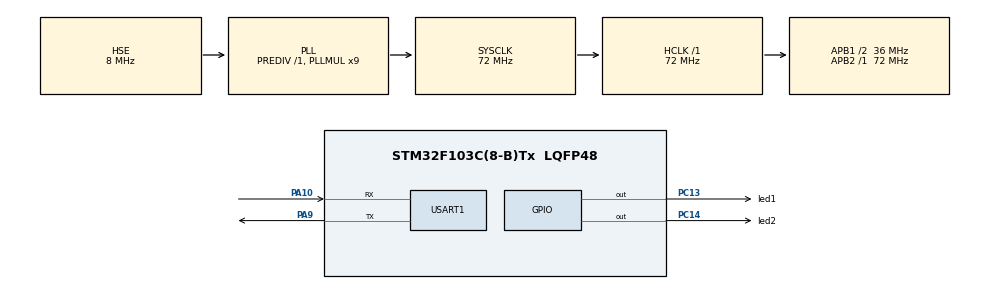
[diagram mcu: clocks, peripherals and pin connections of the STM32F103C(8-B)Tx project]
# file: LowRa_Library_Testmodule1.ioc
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Dma.Request0=USART1_RX
Dma.Request1=USART1_TX
Dma.USART1_RX.0.Direction=DMA_PERIPH_TO_MEMORY
Dma.USART1_RX.0.Instance=DMA1_Channel5
Dma.USART1_RX.0.MemDataAlignment=DMA_MDATAALIGN_BYTE
Dma.USART1_RX.0.MemInc=DMA_MINC_ENABLE
Dma.USART1_RX.0.Mode=DMA_NORMAL
Dma.USART1_RX.0.PeriphDataAlignment=DMA_PDATAALIGN_BYTE
Dma.USART1_RX.0.PeriphInc=DMA_PINC_DISABLE
Dma.USART1_RX.0.Priority=DMA_PRIORITY_LOW
Dma.USART1_TX.1.Direction=DMA_MEMORY_TO_PERIPH
Dma.USART1_TX.1.Instance=DMA1_Channel4
Dma.USART1_TX.1.MemDataAlignment=DMA_MDATAALIGN_BYTE
Dma.USART1_TX.1.MemInc=DMA_MINC_ENABLE
Dma.USART1_TX.1.Mode=DMA_NORMAL
Dma.USART1_TX.1.PeriphDataAlignment=DMA_PDATAALIGN_BYTE
Dma.USART1_TX.1.PeriphInc=DMA_PINC_DISABLE
Dma.USART1_TX.1.Priority=DMA_PRIORITY_LOW
Mcu.Family=STM32F1
Mcu.Name=STM32F103C(8-B)Tx
Mcu.Package=LQFP48
NVIC.DMA1_Channel4_IRQn=true\:0\:0\:false\:false\:true\:false\:true
NVIC.DMA1_Channel5_IRQn=true\:0\:0\:false\:false\:true\:false\:true
NVIC.PriorityGroup=NVIC_PRIORITYGROUP_4
NVIC.USART1_IRQn=true\:0\:0\:false\:false\:true\:true\:true
PA10.Mode=Asynchronous
PA10.Signal=USART1_RX
PA13.Mode=Serial_Wire
PA13.Signal=SYS_JTMS-SWDIO
PA14.Mode=Serial_Wire
PA14.Signal=SYS_JTCK-SWCLK
PA9.Mode=Asynchronous
PA9.Signal=USART1_TX
PC13-TAMPER-RTC.GPIO_Label=led1
PC13-TAMPER-RTC.Signal=GPIO_Output
PC14-OSC32_IN.GPIO_Label=led2
PC14-OSC32_IN.Signal=GPIO_Output
PD0-OSC_IN.Mode=HSE-External-Oscillator
PD0-OSC_IN.Signal=RCC_OSC_IN
PD1-OSC_OUT.Mode=HSE-External-Oscillator
PD1-OSC_OUT.Signal=RCC_OSC_OUT
ProjectManager.HeapSize=0x200
ProjectManager.StackSize=0x400
ProjectManager.TargetToolchain=STM32CubeIDE
RCC.AHBFreq_Value=72000000
RCC.APB1CLKDivider=RCC_HCLK_DIV2
RCC.APB1Freq_Value=36000000
RCC.APB1TimFreq_Value=72000000
RCC.APB2Freq_Value=72000000
RCC.APB2TimFreq_Value=72000000
RCC.HCLKFreq_Value=72000000
RCC.PLLMUL=RCC_PLL_MUL9
RCC.PLLSourceVirtual=RCC_PLLSOURCE_HSE
RCC.SYSCLKFreq_VALUE=72000000
RCC.SYSCLKSource=RCC_SYSCLKSOURCE_PLLCLK
RCC.USBFreq_Value=72000000
USART1.VirtualMode=VM_ASYNC
board=custom

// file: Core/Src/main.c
/* USER CODE BEGIN Header */
/**
  ******************************************************************************
  * @file           : main.c
  * @brief          : Main program body
  ******************************************************************************
  * @attention
  *
  * <h2><center>&copy; Copyright (c) 2021 STMicroelectronics.
  * All rights reserved.</center></h2>
  *
  * This software component is licensed by ST under BSD 3-Clause license,
  * the "License"; You may not use this file except in compliance with the
  * License. You may obtain a copy of the License at:
  *                        opensource.org/licenses/BSD-3-Clause
  *
  ******************************************************************************
  */
/* USER CODE END Header */
#include "main.h"

/* USER CODE BEGIN Includes */
#include "S76s_command_ledblink.h"

/* USER CODE END Includes */

UART_HandleTypeDef huart1;
DMA_HandleTypeDef hdma_usart1_rx;
DMA_HandleTypeDef hdma_usart1_tx;

void SystemClock_Config(void);
static void MX_GPIO_Init(void);
static void MX_DMA_Init(void);
static void MX_USART1_UART_Init(void);

int main(void)
{

  /* MCU Configuration--------------------------------------------------------*/

  /* Reset of all peripherals, Initializes the Flash interface and the Systick. */
  HAL_Init();

  /* Configure the system clock */
  SystemClock_Config();

  /* Initialize all configured peripherals */
  MX_GPIO_Init();
  MX_DMA_Init();
  MX_USART1_UART_Init();

  /* Infinite loop */
  while (1)
  {

    /* USER CODE BEGIN 3 */
	  HAL_UART_Transmit(&huart1, (uint8_t*)LoRa_tx("got the message"), sizeof(LoRa_tx("got the message")), 100);
	  HAL_Delay(1000);
  }
  /* USER CODE END 3 */
}

void SystemClock_Config(void)
{
  RCC_OscInitTypeDef RCC_OscInitStruct = {0};
  RCC_ClkInitTypeDef RCC_ClkInitStruct = {0};

  /** Initializes the RCC Oscillators according to the specified parameters
  * in the RCC_OscInitTypeDef structure.
  */
  RCC_OscInitStruct.OscillatorType = RCC_OSCILLATORTYPE_HSE;
  RCC_OscInitStruct.HSEState = RCC_HSE_ON;
  RCC_OscInitStruct.HSEPredivValue = RCC_HSE_PREDIV_DIV1;
  RCC_OscInitStruct.HSIState = RCC_HSI_ON;
  RCC_OscInitStruct.PLL.PLLState = RCC_PLL_ON;
  RCC_OscInitStruct.PLL.PLLSource = RCC_PLLSOURCE_HSE;
  RCC_OscInitStruct.PLL.PLLMUL = RCC_PLL_MUL9;
  if (HAL_RCC_OscConfig(&RCC_OscInitStruct) != HAL_OK)
  {
    Error_Handler();
  }
  /** Initializes the CPU, AHB and APB buses clocks
  */
  RCC_ClkInitStruct.ClockType = RCC_CLOCKTYPE_HCLK|RCC_CLOCKTYPE_SYSCLK
                              |RCC_CLOCKTYPE_PCLK1|RCC_CLOCKTYPE_PCLK2;
  RCC_ClkInitStruct.SYSCLKSource = RCC_SYSCLKSOURCE_PLLCLK;
  RCC_ClkInitStruct.AHBCLKDivider = RCC_SYSCLK_DIV1;
  RCC_ClkInitStruct.APB1CLKDivider = RCC_HCLK_DIV2;
  RCC_ClkInitStruct.APB2CLKDivider = RCC_HCLK_DIV1;

  if (HAL_RCC_ClockConfig(&RCC_ClkInitStruct, FLASH_LATENCY_2) != HAL_OK)
  {
    Error_Handler();
  }
}

static void MX_USART1_UART_Init(void)
{

  huart1.Instance = USART1;
  huart1.Init.BaudRate = 115200;
  huart1.Init.WordLength = UART_WORDLENGTH_8B;
  huart1.Init.StopBits = UART_STOPBITS_1;
  huart1.Init.Parity = UART_PARITY_NONE;
  huart1.Init.Mode = UART_MODE_TX_RX;
  huart1.Init.HwFlowCtl = UART_HWCONTROL_NONE;
  huart1.Init.OverSampling = UART_OVERSAMPLING_16;
  if (HAL_UART_Init(&huart1) != HAL_OK)
  {
    Error_Handler();
  }

}

static void MX_DMA_Init(void)
{

  /* DMA controller clock enable */
  __HAL_RCC_DMA1_CLK_ENABLE();

  /* DMA interrupt init */
  /* DMA1_Channel4_IRQn interrupt configuration */
  HAL_NVIC_SetPriority(DMA1_Channel4_IRQn, 0, 0);
  HAL_NVIC_EnableIRQ(DMA1_Channel4_IRQn);
  /* DMA1_Channel5_IRQn interrupt configuration */
  HAL_NVIC_SetPriority(DMA1_Channel5_IRQn, 0, 0);
  HAL_NVIC_EnableIRQ(DMA1_Channel5_IRQn);

}

static void MX_GPIO_Init(void)
{
  GPIO_InitTypeDef GPIO_InitStruct = {0};

  /* GPIO Ports Clock Enable */
  __HAL_RCC_GPIOC_CLK_ENABLE();
  __HAL_RCC_GPIOD_CLK_ENABLE();
  __HAL_RCC_GPIOA_CLK_ENABLE();

  /*Configure GPIO pin Output Level */
  HAL_GPIO_WritePin(GPIOC, led1_Pin|led2_Pin, GPIO_PIN_RESET);

  /*Configure GPIO pins : led1_Pin led2_Pin */
  GPIO_InitStruct.Pin = led1_Pin|led2_Pin;
  GPIO_InitStruct.Mode = GPIO_MODE_OUTPUT_PP;
  GPIO_InitStruct.Pull = GPIO_NOPULL;
  GPIO_InitStruct.Speed = GPIO_SPEED_FREQ_LOW;
  HAL_GPIO_Init(GPIOC, &GPIO_InitStruct);

}

void Error_Handler(void)
{
  __disable_irq();
  while (1)
  {
  }
}

/************************ (C) COPYRIGHT STMicroelectronics *****END OF FILE****/
